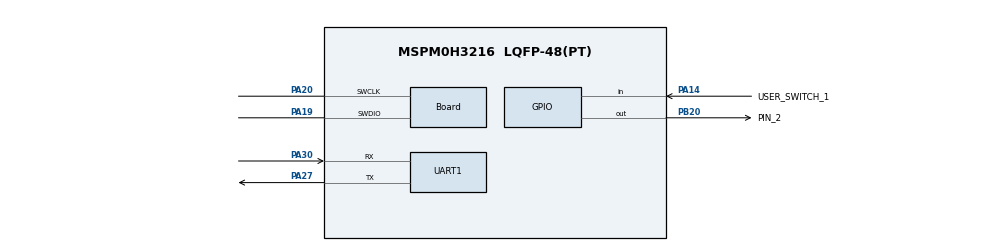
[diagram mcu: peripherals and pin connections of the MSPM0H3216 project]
//@cliArgs --device "MSPM0H321X" --package "LQFP-48(PT)" --part "Default"
//@v2CliArgs --device "MSPM0H3216" --package "LQFP-48(PT)"
// @cliArgs --board /ti/boards/LP_MSPM0H3216 --rtos nortos

/**
 * Import the modules used in this configuration.
 */
const GPIO          = scripting.addModule("/ti/driverlib/GPIO", {}, false);
const GPIO1         = GPIO.addInstance();
const GPIO2         = GPIO.addInstance();
const GPIO3         = GPIO.addInstance();
const UART          = scripting.addModule("/ti/driverlib/UART", {}, false);
const UART1         = UART.addInstance();
const ProjectConfig = scripting.addModule("/ti/project_config/ProjectConfig");

/**
 * Write custom configuration values to the imported modules.
 */
GPIO1.$name                   = "GPIO_LED1";
GPIO1.associatedPins[0].$name = "PIN_1";

const Board                       = scripting.addModule("/ti/driverlib/Board", {}, false);
Board.peripheral.$assign          = "DEBUGSS";
Board.peripheral.swclkPin.$assign = "PA20";
Board.peripheral.swdioPin.$assign = "PA19";

GPIO2.$name                              = "GPIO_SWITCHES";
GPIO2.associatedPins[0].direction        = "INPUT";
GPIO2.associatedPins[0].interruptEn      = true;
GPIO2.associatedPins[0].polarity         = "FALL";
GPIO2.associatedPins[0].internalResistor = "PULL_UP";
GPIO2.associatedPins[0].$name            = "USER_SWITCH_1";
GPIO2.associatedPins[0].pin.$assign      = "PA14";

GPIO3.$name                         = "GPIO_LED2";
GPIO3.associatedPins[0].$name       = "PIN_2";
GPIO3.associatedPins[0].pin.$assign = "PB20";

const SYSCTL              = scripting.addModule("/ti/driverlib/SYSCTL", {}, false);
SYSCTL.peripheral.$assign = "SYSCTL";

UART1.$name                    = "UART_0";
UART1.enabledInterrupts        = ["RX"];
UART1.peripheral.$assign       = "UART0";
UART1.peripheral.rxPin.$assign = "PA30";
UART1.peripheral.txPin.$assign = "PA27";

ProjectConfig.genLinker          = false;
ProjectConfig.migrationCondition = true;
scripting.suppress("All four File Generation options must be enabled in order to guarantee Device Migration support\\. If an option is disabled, the user must manually configure that setting on its own file\\.", ProjectConfig);
